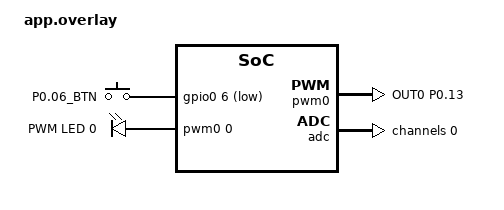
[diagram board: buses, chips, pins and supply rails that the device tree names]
/ {
	aliases {
		/* Handy handles used by the app */
		button6 = &p006_in;
		my-adc = &adc;
		my-adc-channel = &adc0_ch0;
		pwm-led0 = &pwm_led0;
	};

	/* Button on P0.06 (active-low, internal pull-up) */
	buttons {
		compatible = "gpio-keys";
		p006_in: p006_in {
			gpios = <&gpio0 6 (GPIO_PULL_UP | GPIO_ACTIVE_LOW)>;
			label = "P0.06_BTN";
		};
	};

	/* PWM-controlled LED */
	pwmleds {
		compatible = "pwm-leds";
		pwm_led0: pwm_led_0 {
			/* &pwm0, channel 0, period=1 ms (1 kHz), inverted (LEDs are active-low) */
			pwms = <&pwm0 0 PWM_MSEC(1) PWM_POLARITY_INVERTED>;
			label = "PWM LED 0";
		};
	};
};

/* We'll repurpose LED1 (on P0.13) for PWM, so disable the default GPIO LED0 node */
&led0 {
	status = "disabled";
};

/* Enable PWM0 and route its channel 0 to P0.13 */
&pwm0 {
	status = "okay";
	pinctrl-0 = <&pwm0_default>;
	pinctrl-1 = <&pwm0_sleep>;
	pinctrl-names = "default", "sleep";
};

&pinctrl {
	pwm0_default: pwm0_default {
		group1 {
			/* PWM channel 0 -> Port 0, Pin 13 (P0.13) */
			psels = <NRF_PSEL(PWM_OUT0, 0, 13)>;
		};
	};

	pwm0_sleep: pwm0_sleep {
		group1 {
			psels = <NRF_PSEL(PWM_OUT0, 0, 13)>;
			low-power-enable;
		};
	};
};

/* SAADC (ADC) with Channel 0 on AIN2 (P0.04) */
&adc {
	status = "okay";
	#address-cells = <1>;
	#size-cells = <0>;

	adc0_ch0: channel@0 {
		reg = <0>;
		zephyr,gain = "ADC_GAIN_1_4";
		/* Vref = VDD/4. With gain=1/4, full-scale becomes VDD — nice and simple. */
		zephyr,reference = "ADC_REF_VDD_1_4";
		zephyr,acquisition-time = <ADC_ACQ_TIME_DEFAULT>;
		zephyr,input-positive = <NRF_SAADC_AIN2>; /* P0.04 */
		zephyr,resolution = <12>;
	};
};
